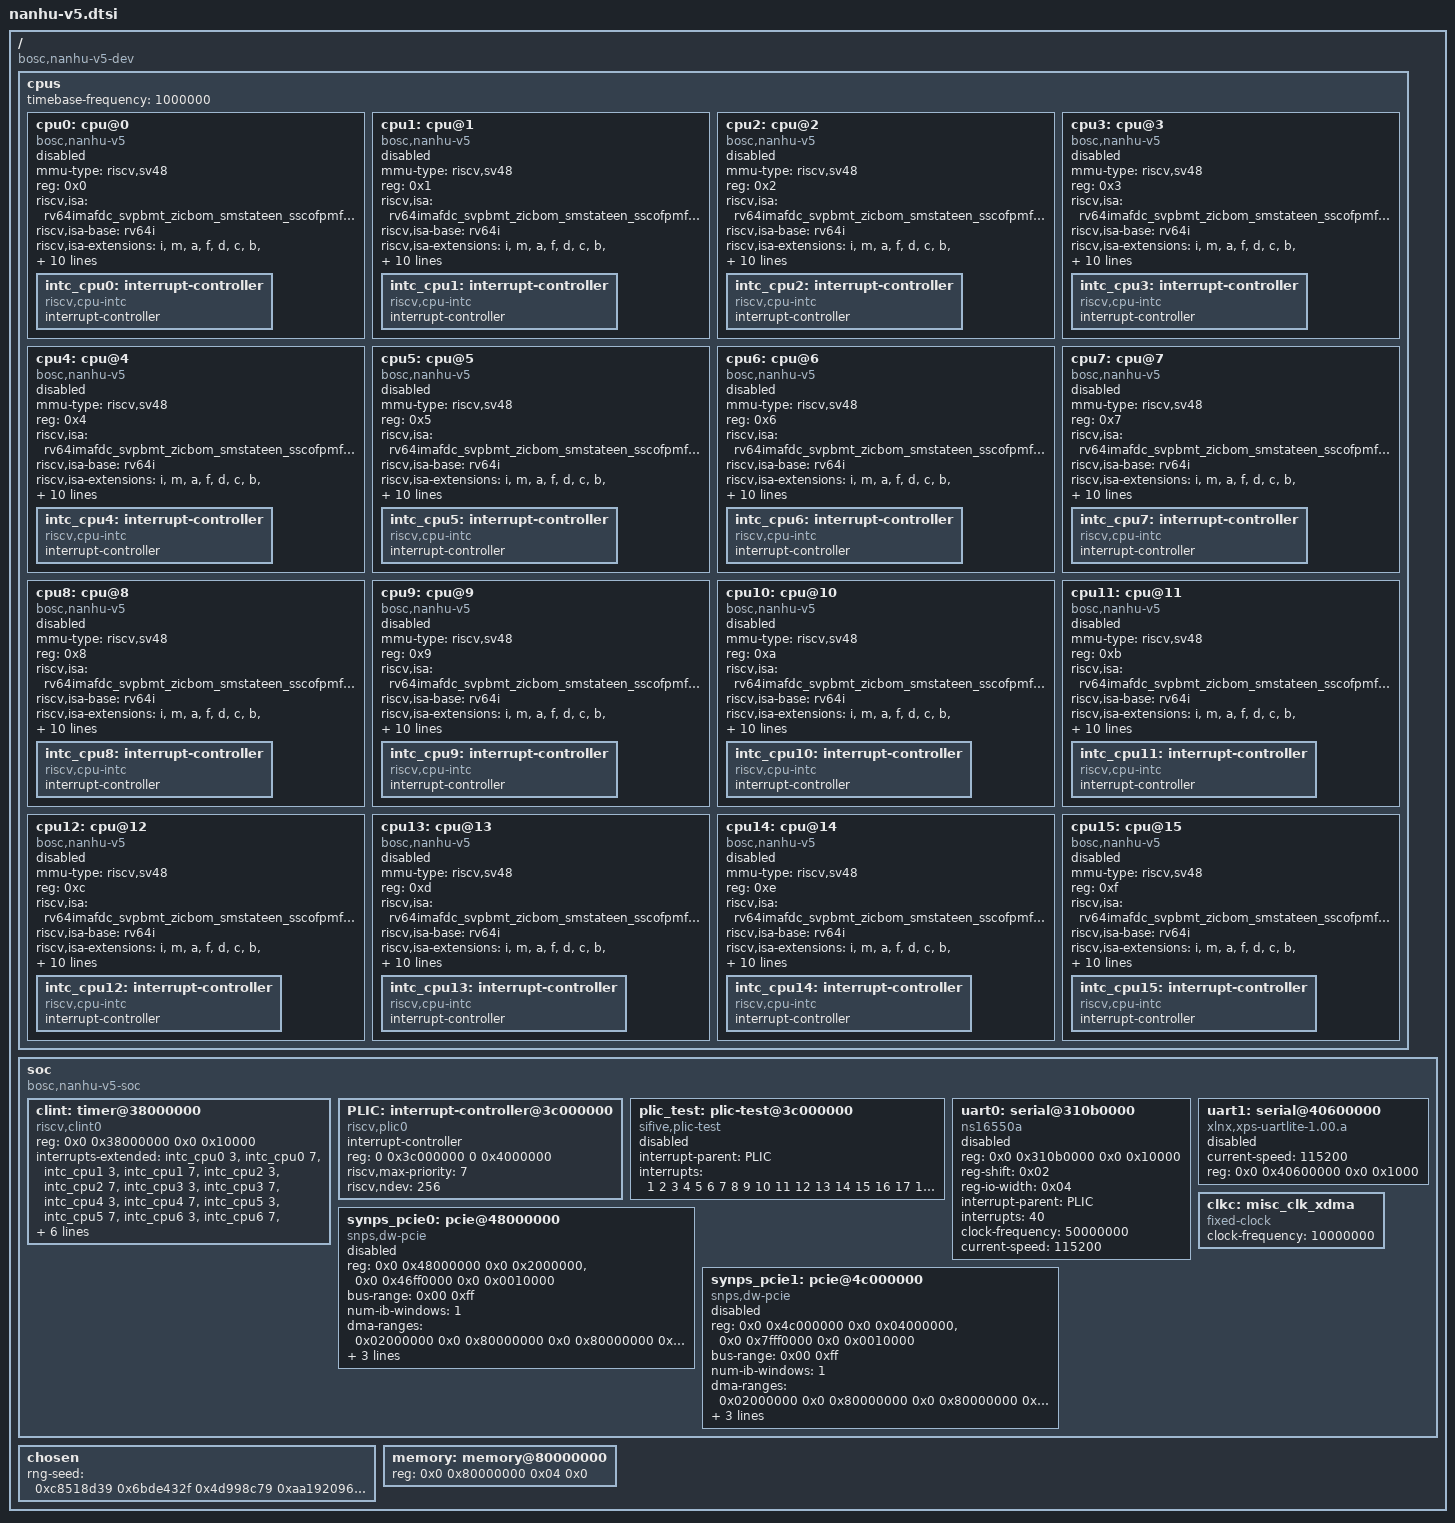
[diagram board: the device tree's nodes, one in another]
// SPDX-License-Identifier: (GPL-2.0 OR MIT)
/* Copyright (c) 2025 BOSC */

/dts-v1/;
#include <dt-bindings/interrupt-controller/irq.h>
/ {
	compatible = "bosc,nanhu-v5-dev";
	#address-cells = <2>;
	#size-cells = <2>;

	cpus {
		#address-cells = <1>;
		#size-cells = <0>;
		timebase-frequency = <1000000>; /* 1Mhz */

		cpu0: cpu@0 {
			compatible = "bosc,nanhu-v5", "riscv";
			device_type = "cpu";
			mmu-type = "riscv,sv48";
			reg = <0x0>;
			riscv,isa = "rv64imafdc_svpbmt_zicbom_smstateen_sscofpmf_zicntr_zihpm_zicboz_sdtrig_svade_zicboz_zicbom";
			riscv,isa-base = "rv64i";
			riscv,isa-extensions = "i", "m", "a", "f", "d", "c","b", "zifencei","zicsr","zicntr", "zihpm", "zba", "zbb", "zbc", "zbs", "zkn", "zknd", "zkne","zknh", "zks", "zksed",
						"zksh", "zkt","zicbom","zicbop", "zicboz","zicond","zimop", "zcmop","zcb", "zbkb", "zbkc", "zbkx", "svpbmt", "svinval","sstc",
						"sscofpmf", "ssstateen", "smstateen", "ziccif", "ziccrse", "ziccamoa", "za64rs", "zic64b", "svbare", "svade", "ssccptr", "sscounterenw",
						"sstvecd", "sstvala", "ssu64xl";

			riscv,cbom-block-size = <0x40>;
			riscv,cboz-block-size = <0x40>;

                        status = "disabled";

			intc_cpu0: interrupt-controller {
				#interrupt-cells = <1>;
				compatible = "riscv,cpu-intc";
				interrupt-controller;
			};
		};

		cpu1: cpu@1 {
			compatible = "bosc,nanhu-v5", "riscv";
			device_type = "cpu";
			mmu-type = "riscv,sv48";
			reg = <0x1>;
			riscv,isa = "rv64imafdc_svpbmt_zicbom_smstateen_sscofpmf_zicntr_zihpm_zicboz_sdtrig_svade_zicboz_zicbom";
			riscv,isa-base = "rv64i";
			riscv,isa-extensions = "i", "m", "a", "f", "d", "c","b", "zifencei","zicsr","zicntr", "zihpm", "zba", "zbb", "zbc", "zbs", "zkn", "zknd", "zkne","zknh", "zks", "zksed",
						"zksh", "zkt","zicbom","zicbop", "zicboz","zicond","zimop", "zcmop","zcb", "zbkb", "zbkc", "zbkx", "svpbmt", "svinval","sstc",
						"sscofpmf", "ssstateen", "smstateen", "ziccif", "ziccrse", "ziccamoa", "za64rs", "zic64b", "svbare", "svade", "ssccptr", "sscounterenw",
						"sstvecd", "sstvala", "ssu64xl";
			riscv,cbom-block-size = <0x40>;
			riscv,cboz-block-size = <0x40>;

                        status = "disabled";

			intc_cpu1: interrupt-controller {
				#interrupt-cells = <1>;
				compatible = "riscv,cpu-intc";
				interrupt-controller;
			};
		};

		cpu2: cpu@2 {
			compatible = "bosc,nanhu-v5", "riscv";
			device_type = "cpu";
			mmu-type = "riscv,sv48";
			reg = <0x2>;
			riscv,isa = "rv64imafdc_svpbmt_zicbom_smstateen_sscofpmf_zicntr_zihpm_zicboz_sdtrig_svade_zicboz_zicbom";
			riscv,isa-base = "rv64i";
			riscv,isa-extensions = "i", "m", "a", "f", "d", "c","b", "zifencei","zicsr","zicntr", "zihpm", "zba", "zbb", "zbc", "zbs", "zkn", "zknd", "zkne","zknh", "zks", "zksed",
						"zksh", "zkt","zicbom","zicbop", "zicboz","zicond","zimop", "zcmop","zcb", "zbkb", "zbkc", "zbkx", "svpbmt", "svinval","sstc",
						"sscofpmf", "ssstateen", "smstateen", "ziccif", "ziccrse", "ziccamoa", "za64rs", "zic64b", "svbare", "svade", "ssccptr", "sscounterenw",
						"sstvecd", "sstvala", "ssu64xl";
			riscv,cbom-block-size = <0x40>;
			riscv,cboz-block-size = <0x40>;

                        status = "disabled";

			intc_cpu2: interrupt-controller {
				#interrupt-cells = <1>;
				compatible = "riscv,cpu-intc";
				interrupt-controller;
			};
		};

		cpu3: cpu@3 {
			compatible = "bosc,nanhu-v5", "riscv";
			device_type = "cpu";
			mmu-type = "riscv,sv48";
			reg = <0x3>;
			riscv,isa = "rv64imafdc_svpbmt_zicbom_smstateen_sscofpmf_zicntr_zihpm_zicboz_sdtrig_svade_zicboz_zicbom";
			riscv,isa-base = "rv64i";
			riscv,isa-extensions = "i", "m", "a", "f", "d", "c","b", "zifencei","zicsr","zicntr", "zihpm", "zba", "zbb", "zbc", "zbs", "zkn", "zknd", "zkne","zknh", "zks", "zksed",
						"zksh", "zkt","zicbom","zicbop", "zicboz","zicond","zimop", "zcmop","zcb", "zbkb", "zbkc", "zbkx", "svpbmt", "svinval","sstc",
						"sscofpmf", "ssstateen", "smstateen", "ziccif", "ziccrse", "ziccamoa", "za64rs", "zic64b", "svbare", "svade", "ssccptr", "sscounterenw",
						"sstvecd", "sstvala", "ssu64xl";
			riscv,cbom-block-size = <0x40>;
			riscv,cboz-block-size = <0x40>;

                        status = "disabled";

			intc_cpu3: interrupt-controller {
				#interrupt-cells = <1>;
				compatible = "riscv,cpu-intc";
				interrupt-controller;
			};
		};

		cpu4: cpu@4 {
			compatible = "bosc,nanhu-v5", "riscv";
			device_type = "cpu";
			mmu-type = "riscv,sv48";
			reg = <0x4>;
			riscv,isa = "rv64imafdc_svpbmt_zicbom_smstateen_sscofpmf_zicntr_zihpm_zicboz_sdtrig_svade_zicboz_zicbom";
			riscv,isa-base = "rv64i";
			riscv,isa-extensions = "i", "m", "a", "f", "d", "c","b", "zifencei","zicsr","zicntr", "zihpm", "zba", "zbb", "zbc", "zbs", "zkn", "zknd", "zkne","zknh", "zks", "zksed",
						"zksh", "zkt","zicbom","zicbop", "zicboz","zicond","zimop", "zcmop","zcb", "zbkb", "zbkc", "zbkx", "svpbmt", "svinval","sstc",
						"sscofpmf", "ssstateen", "smstateen", "ziccif", "ziccrse", "ziccamoa", "za64rs", "zic64b", "svbare", "svade", "ssccptr", "sscounterenw",
						"sstvecd", "sstvala", "ssu64xl";
			riscv,cbom-block-size = <0x40>;
			riscv,cboz-block-size = <0x40>;

                        status = "disabled";

			intc_cpu4: interrupt-controller {
				#interrupt-cells = <1>;
				compatible = "riscv,cpu-intc";
				interrupt-controller;
			};
		};

		cpu5: cpu@5 {
			compatible = "bosc,nanhu-v5", "riscv";
			device_type = "cpu";
			mmu-type = "riscv,sv48";
			reg = <0x5>;
			riscv,isa = "rv64imafdc_svpbmt_zicbom_smstateen_sscofpmf_zicntr_zihpm_zicboz_sdtrig_svade_zicboz_zicbom";
			riscv,isa-base = "rv64i";
			riscv,isa-extensions = "i", "m", "a", "f", "d", "c","b", "zifencei","zicsr","zicntr", "zihpm", "zba", "zbb", "zbc", "zbs", "zkn", "zknd", "zkne","zknh", "zks", "zksed",
						"zksh", "zkt","zicbom","zicbop", "zicboz","zicond","zimop", "zcmop","zcb", "zbkb", "zbkc", "zbkx", "svpbmt", "svinval","sstc",
						"sscofpmf", "ssstateen", "smstateen", "ziccif", "ziccrse", "ziccamoa", "za64rs", "zic64b", "svbare", "svade", "ssccptr", "sscounterenw",
						"sstvecd", "sstvala", "ssu64xl";
			riscv,cbom-block-size = <0x40>;
			riscv,cboz-block-size = <0x40>;

                        status = "disabled";

			intc_cpu5: interrupt-controller {
				#interrupt-cells = <1>;
				compatible = "riscv,cpu-intc";
				interrupt-controller;
			};
		};

		cpu6: cpu@6 {
			compatible = "bosc,nanhu-v5", "riscv";
			device_type = "cpu";
			mmu-type = "riscv,sv48";
			reg = <0x6>;
			riscv,isa = "rv64imafdc_svpbmt_zicbom_smstateen_sscofpmf_zicntr_zihpm_zicboz_sdtrig_svade_zicboz_zicbom";
			riscv,isa-base = "rv64i";
			riscv,isa-extensions = "i", "m", "a", "f", "d", "c","b", "zifencei","zicsr","zicntr", "zihpm", "zba", "zbb", "zbc", "zbs", "zkn", "zknd", "zkne","zknh", "zks", "zksed",
						"zksh", "zkt","zicbom","zicbop", "zicboz","zicond","zimop", "zcmop","zcb", "zbkb", "zbkc", "zbkx", "svpbmt", "svinval","sstc",
						"sscofpmf", "ssstateen", "smstateen", "ziccif", "ziccrse", "ziccamoa", "za64rs", "zic64b", "svbare", "svade", "ssccptr", "sscounterenw",
						"sstvecd", "sstvala", "ssu64xl";
			riscv,cbom-block-size = <0x40>;
			riscv,cboz-block-size = <0x40>;

                        status = "disabled";

			intc_cpu6: interrupt-controller {
				#interrupt-cells = <1>;
				compatible = "riscv,cpu-intc";
				interrupt-controller;
			};
		};

		cpu7: cpu@7 {
			compatible = "bosc,nanhu-v5", "riscv";
			device_type = "cpu";
			mmu-type = "riscv,sv48";
			reg = <0x7>;
			riscv,isa = "rv64imafdc_svpbmt_zicbom_smstateen_sscofpmf_zicntr_zihpm_zicboz_sdtrig_svade_zicboz_zicbom";
			riscv,isa-base = "rv64i";
			riscv,isa-extensions = "i", "m", "a", "f", "d", "c","b", "zifencei","zicsr","zicntr", "zihpm", "zba", "zbb", "zbc", "zbs", "zkn", "zknd", "zkne","zknh", "zks", "zksed",
						"zksh", "zkt","zicbom","zicbop", "zicboz","zicond","zimop", "zcmop","zcb", "zbkb", "zbkc", "zbkx", "svpbmt", "svinval","sstc",
						"sscofpmf", "ssstateen", "smstateen", "ziccif", "ziccrse", "ziccamoa", "za64rs", "zic64b", "svbare", "svade", "ssccptr", "sscounterenw",
						"sstvecd", "sstvala", "ssu64xl";
			riscv,cbom-block-size = <0x40>;
			riscv,cboz-block-size = <0x40>;

                        status = "disabled";

			intc_cpu7: interrupt-controller {
				#interrupt-cells = <1>;
				compatible = "riscv,cpu-intc";
				interrupt-controller;
			};
		};

		cpu8: cpu@8 {
			compatible = "bosc,nanhu-v5", "riscv";
			device_type = "cpu";
			mmu-type = "riscv,sv48";
			reg = <0x8>;
			riscv,isa = "rv64imafdc_svpbmt_zicbom_smstateen_sscofpmf_zicntr_zihpm_zicboz_sdtrig_svade_zicboz_zicbom";
			riscv,isa-base = "rv64i";
			riscv,isa-extensions = "i", "m", "a", "f", "d", "c","b", "zifencei","zicsr","zicntr", "zihpm", "zba", "zbb", "zbc", "zbs", "zkn", "zknd", "zkne","zknh", "zks", "zksed",
						"zksh", "zkt","zicbom","zicbop", "zicboz","zicond","zimop", "zcmop","zcb", "zbkb", "zbkc", "zbkx", "svpbmt", "svinval","sstc",
						"sscofpmf", "ssstateen", "smstateen", "ziccif", "ziccrse", "ziccamoa", "za64rs", "zic64b", "svbare", "svade", "ssccptr", "sscounterenw",
						"sstvecd", "sstvala", "ssu64xl";
			riscv,cbom-block-size = <0x40>;
			riscv,cboz-block-size = <0x40>;

                        status = "disabled";

			intc_cpu8: interrupt-controller {
				#interrupt-cells = <1>;
				compatible = "riscv,cpu-intc";
				interrupt-controller;
			};
		};

		cpu9: cpu@9 {
			compatible = "bosc,nanhu-v5", "riscv";
			device_type = "cpu";
			mmu-type = "riscv,sv48";
			reg = <0x9>;
			riscv,isa = "rv64imafdc_svpbmt_zicbom_smstateen_sscofpmf_zicntr_zihpm_zicboz_sdtrig_svade_zicboz_zicbom";
			riscv,isa-base = "rv64i";
			riscv,isa-extensions = "i", "m", "a", "f", "d", "c","b", "zifencei","zicsr","zicntr", "zihpm", "zba", "zbb", "zbc", "zbs", "zkn", "zknd", "zkne","zknh", "zks", "zksed",
						"zksh", "zkt","zicbom","zicbop", "zicboz","zicond","zimop", "zcmop","zcb", "zbkb", "zbkc", "zbkx", "svpbmt", "svinval","sstc",
						"sscofpmf", "ssstateen", "smstateen", "ziccif", "ziccrse", "ziccamoa", "za64rs", "zic64b", "svbare", "svade", "ssccptr", "sscounterenw",
						"sstvecd", "sstvala", "ssu64xl";
			riscv,cbom-block-size = <0x40>;
			riscv,cboz-block-size = <0x40>;

                        status = "disabled";

			intc_cpu9: interrupt-controller {
				#interrupt-cells = <1>;
				compatible = "riscv,cpu-intc";
				interrupt-controller;
			};
		};

		cpu10: cpu@10 {
			compatible = "bosc,nanhu-v5", "riscv";
			device_type = "cpu";
			mmu-type = "riscv,sv48";
			reg = <0xa>;
			riscv,isa = "rv64imafdc_svpbmt_zicbom_smstateen_sscofpmf_zicntr_zihpm_zicboz_sdtrig_svade_zicboz_zicbom";
			riscv,isa-base = "rv64i";
			riscv,isa-extensions = "i", "m", "a", "f", "d", "c","b", "zifencei","zicsr","zicntr", "zihpm", "zba", "zbb", "zbc", "zbs", "zkn", "zknd", "zkne","zknh", "zks", "zksed",
						"zksh", "zkt","zicbom","zicbop", "zicboz","zicond","zimop", "zcmop","zcb", "zbkb", "zbkc", "zbkx", "svpbmt", "svinval","sstc",
						"sscofpmf", "ssstateen", "smstateen", "ziccif", "ziccrse", "ziccamoa", "za64rs", "zic64b", "svbare", "svade", "ssccptr", "sscounterenw",
						"sstvecd", "sstvala", "ssu64xl";
			riscv,cbom-block-size = <0x40>;
			riscv,cboz-block-size = <0x40>;

                        status = "disabled";

			intc_cpu10: interrupt-controller {
				#interrupt-cells = <1>;
				compatible = "riscv,cpu-intc";
				interrupt-controller;
			};
		};

		cpu11: cpu@11 {
			compatible = "bosc,nanhu-v5", "riscv";
			device_type = "cpu";
			mmu-type = "riscv,sv48";
			reg = <0xb>;
			riscv,isa = "rv64imafdc_svpbmt_zicbom_smstateen_sscofpmf_zicntr_zihpm_zicboz_sdtrig_svade_zicboz_zicbom";
			riscv,isa-base = "rv64i";
			riscv,isa-extensions = "i", "m", "a", "f", "d", "c","b", "zifencei","zicsr","zicntr", "zihpm", "zba", "zbb", "zbc", "zbs", "zkn", "zknd", "zkne","zknh", "zks", "zksed",
						"zksh", "zkt","zicbom","zicbop", "zicboz","zicond","zimop", "zcmop","zcb", "zbkb", "zbkc", "zbkx", "svpbmt", "svinval","sstc",
						"sscofpmf", "ssstateen", "smstateen", "ziccif", "ziccrse", "ziccamoa", "za64rs", "zic64b", "svbare", "svade", "ssccptr", "sscounterenw",
						"sstvecd", "sstvala", "ssu64xl";
			riscv,cbom-block-size = <0x40>;
			riscv,cboz-block-size = <0x40>;

                        status = "disabled";

			intc_cpu11: interrupt-controller {
				#interrupt-cells = <1>;
				compatible = "riscv,cpu-intc";
				interrupt-controller;
			};
		};

		cpu12: cpu@12 {
			compatible = "bosc,nanhu-v5", "riscv";
			device_type = "cpu";
			mmu-type = "riscv,sv48";
			reg = <0xc>;
			riscv,isa = "rv64imafdc_svpbmt_zicbom_smstateen_sscofpmf_zicntr_zihpm_zicboz_sdtrig_svade_zicboz_zicbom";
			riscv,isa-base = "rv64i";
			riscv,isa-extensions = "i", "m", "a", "f", "d", "c","b", "zifencei","zicsr","zicntr", "zihpm", "zba", "zbb", "zbc", "zbs", "zkn", "zknd", "zkne","zknh", "zks", "zksed",
						"zksh", "zkt","zicbom","zicbop", "zicboz","zicond","zimop", "zcmop","zcb", "zbkb", "zbkc", "zbkx", "svpbmt", "svinval","sstc",
						"sscofpmf", "ssstateen", "smstateen", "ziccif", "ziccrse", "ziccamoa", "za64rs", "zic64b", "svbare", "svade", "ssccptr", "sscounterenw",
						"sstvecd", "sstvala", "ssu64xl";
			riscv,cbom-block-size = <0x40>;
			riscv,cboz-block-size = <0x40>;

                        status = "disabled";

			intc_cpu12: interrupt-controller {
				#interrupt-cells = <1>;
				compatible = "riscv,cpu-intc";
				interrupt-controller;
			};
		};

		cpu13: cpu@13 {
			compatible = "bosc,nanhu-v5", "riscv";
			device_type = "cpu";
			mmu-type = "riscv,sv48";
			reg = <0xd>;
			riscv,isa = "rv64imafdc_svpbmt_zicbom_smstateen_sscofpmf_zicntr_zihpm_zicboz_sdtrig_svade_zicboz_zicbom";
			riscv,isa-base = "rv64i";
			riscv,isa-extensions = "i", "m", "a", "f", "d", "c","b", "zifencei","zicsr","zicntr", "zihpm", "zba", "zbb", "zbc", "zbs", "zkn", "zknd", "zkne","zknh", "zks", "zksed",
						"zksh", "zkt","zicbom","zicbop", "zicboz","zicond","zimop", "zcmop","zcb", "zbkb", "zbkc", "zbkx", "svpbmt", "svinval","sstc",
						"sscofpmf", "ssstateen", "smstateen", "ziccif", "ziccrse", "ziccamoa", "za64rs", "zic64b", "svbare", "svade", "ssccptr", "sscounterenw",
						"sstvecd", "sstvala", "ssu64xl";
			riscv,cbom-block-size = <0x40>;
			riscv,cboz-block-size = <0x40>;

                        status = "disabled";

			intc_cpu13: interrupt-controller {
				#interrupt-cells = <1>;
				compatible = "riscv,cpu-intc";
				interrupt-controller;
			};
		};

		cpu14: cpu@14 {
			compatible = "bosc,nanhu-v5", "riscv";
			device_type = "cpu";
			mmu-type = "riscv,sv48";
			reg = <0xe>;
			riscv,isa = "rv64imafdc_svpbmt_zicbom_smstateen_sscofpmf_zicntr_zihpm_zicboz_sdtrig_svade_zicboz_zicbom";
			riscv,isa-base = "rv64i";
			riscv,isa-extensions = "i", "m", "a", "f", "d", "c","b", "zifencei","zicsr","zicntr", "zihpm", "zba", "zbb", "zbc", "zbs", "zkn", "zknd", "zkne","zknh", "zks", "zksed",
						"zksh", "zkt","zicbom","zicbop", "zicboz","zicond","zimop", "zcmop","zcb", "zbkb", "zbkc", "zbkx", "svpbmt", "svinval","sstc",
						"sscofpmf", "ssstateen", "smstateen", "ziccif", "ziccrse", "ziccamoa", "za64rs", "zic64b", "svbare", "svade", "ssccptr", "sscounterenw",
						"sstvecd", "sstvala", "ssu64xl";
			riscv,cbom-block-size = <0x40>;
			riscv,cboz-block-size = <0x40>;

                        status = "disabled";

			intc_cpu14: interrupt-controller {
				#interrupt-cells = <1>;
				compatible = "riscv,cpu-intc";
				interrupt-controller;
			};
		};

		cpu15: cpu@15 {
			compatible = "bosc,nanhu-v5", "riscv";
			device_type = "cpu";
			mmu-type = "riscv,sv48";
			reg = <0xf>;
			riscv,isa = "rv64imafdc_svpbmt_zicbom_smstateen_sscofpmf_zicntr_zihpm_zicboz_sdtrig_svade_zicboz_zicbom";
			riscv,isa-base = "rv64i";
			riscv,isa-extensions = "i", "m", "a", "f", "d", "c","b", "zifencei","zicsr","zicntr", "zihpm", "zba", "zbb", "zbc", "zbs", "zkn", "zknd", "zkne","zknh", "zks", "zksed",
						"zksh", "zkt","zicbom","zicbop", "zicboz","zicond","zimop", "zcmop","zcb", "zbkb", "zbkc", "zbkx", "svpbmt", "svinval","sstc",
						"sscofpmf", "ssstateen", "smstateen", "ziccif", "ziccrse", "ziccamoa", "za64rs", "zic64b", "svbare", "svade", "ssccptr", "sscounterenw",
						"sstvecd", "sstvala", "ssu64xl";
			riscv,cbom-block-size = <0x40>;
			riscv,cboz-block-size = <0x40>;

                        status = "disabled";

			intc_cpu15: interrupt-controller {
				#interrupt-cells = <1>;
				compatible = "riscv,cpu-intc";
				interrupt-controller;
			};
		};
	};

	soc {
		#address-cells = <2>;
		#size-cells = <2>;
		compatible = "bosc,nanhu-v5-soc", "simple-bus";
		ranges;

		clint: timer@38000000 {
			compatible = "riscv,clint0";
			reg = <0x0 0x38000000 0x0 0x10000>;
			interrupts-extended =
				<&intc_cpu0 3>, <&intc_cpu0 7>,
				<&intc_cpu1 3>, <&intc_cpu1 7>,
				<&intc_cpu2 3>, <&intc_cpu2 7>,
				<&intc_cpu3 3>, <&intc_cpu3 7>,
				<&intc_cpu4 3>, <&intc_cpu4 7>,
				<&intc_cpu5 3>, <&intc_cpu5 7>,
				<&intc_cpu6 3>, <&intc_cpu6 7>,
				<&intc_cpu7 3>, <&intc_cpu7 7>,
				<&intc_cpu8 3>, <&intc_cpu8 7>,
				<&intc_cpu9 3>, <&intc_cpu9 7>,
				<&intc_cpu10 3>, <&intc_cpu10 7>,
				<&intc_cpu11 3>, <&intc_cpu11 7>,
				<&intc_cpu12 3>, <&intc_cpu12 7>,
				<&intc_cpu13 3>, <&intc_cpu13 7>,
				<&intc_cpu14 3>, <&intc_cpu14 7>,
				<&intc_cpu15 3>, <&intc_cpu15 7>;
		};

		PLIC: interrupt-controller@3c000000 {
			#interrupt-cells = <1>;
			compatible = "riscv,plic0";
			interrupt-controller;
			reg = <0 0x3c000000 0 0x4000000>;
			reg-names = "control";
			riscv,max-priority = <7>;
			riscv,ndev = <256>;
		};

		plic_test: plic-test@3c000000 {
			compatible = "sifive,plic-test";
			interrupt-parent = <&PLIC>;
			/* 定义需要测试的中断号 */
			interrupt-names = "1", "2", "3", "4", "5", "6", "7", "8", "9", "10", "11", "12", "13", "14", "15", "16", "17", "18", "19", "20",
							  "21", "22", "23", "24", "25", "26", "27", "28", "29", "30", "31", "32", "33", "34", "35", "36", "37", "38", "39",
							  "41", "42", "43", "44", "45", "46", "47", "48", "49", "50", "51", "52", "53", "54", "55", "56", "57", "58",
							  "59", "60", "61", "62", "63", "64", "65", "66", "67", "68", "69", "70", "71", "72", "73", "74", "75", "76",
							  "77", "78", "79", "80", "81", "82", "83", "84", "85", "86", "87", "88", "89", "90", "91", "92", "93", "94",
							  "95", "96", "97", "98", "99", "100", "101", "102", "103", "104", "105", "106", "107", "108", "109", "110",
							  "111", "112", "113", "114", "115", "116", "117", "118", "119", "120", "121", "122", "123", "124", "125", "126",
							  "127", "128", "129", "130", "131", "132", "133", "134", "135", "136", "137", "138", "139", "140", "141", "142",
							  "143", "144", "145", "146", "147", "148", "149", "150", "151", "152", "153", "154", "155", "156", "157", "158",
							  "159", "160", "161", "162", "163", "164", "165", "166", "167", "168", "169", "170", "171", "172", "173", "174",
							  "175", "176", "177", "178", "179", "180", "181", "182", "183", "184", "185", "186", "187", "188", "189", "190",
							  "191", "192", "193", "194", "195", "196", "197", "198", "199", "200", "201", "202", "203", "204", "205", "206",
							  "207", "208", "209", "210", "211", "212", "213", "214", "215", "216", "217", "218", "219", "220", "221", "222",
							  "223", "224", "225", "226", "227", "228", "229", "230", "231", "232", "233", "234", "235", "236", "237", "238",
							  "239", "240", "241", "242", "243", "244", "245", "246", "247", "248", "249", "250", "251", "252", "253", "254", "255", "256";
			interrupts = <1    2    3    4    5    6    7    8    9    10    11    12    13    14  
						  15    16    17    18    19    20    21    22    23    24    25    26    27    28  
						  29    30    31    32    33    34    35    36    37    38    39    41    42  
						  43    44    45    46    47    48    49    50    51    52    53    54    55    56  
						  57    58    59    60    61    62    63    64    65    66    67    68    69    70  
						  71    72    73    74    75    76    77    78    79    80    81    82    83    84  
						  85    86    87    88    89    90    91    92    93    94    95    96    97    98  
						  99    100    101    102    103    104    105    106    107    108    109    110    111  
						  112    113    114    115    116    117    118    119    120    121    122    123    124  
						  125    126    127    128    129    130    131    132    133    134    135    136    137  
						  138    139    140    141    142    143    144    145    146    147    148    149    150  
						  151    152    153    154    155    156    157    158    159    160    161    162    163  
						  164    165    166    167    168    169    170    171    172    173    174    175    176  
						  177    178    179    180    181    182    183    184    185    186    187    188    189  
						  190    191    192    193    194    195    196    197    198    199    200    201    202  
						  203    204    205    206    207    208    209    210    211    212    213    214    215  
						  216    217    218    219    220    221    222    223    224    225    226    227    228  
						  229    230    231    232    233    234    235    236    237    238    239    240    241  
						  242    243    244    245    246    247    248    249    250    251    252    253    254  
						  255    256 >;
			status = "disabled";
		};

		uart0: serial@310b0000 {
			compatible = "ns16550a";
			reg = <0x0 0x310b0000 0x0 0x10000>;
			reg-shift = <0x02>;
			reg-io-width = <0x04>;
			interrupt-parent = <&PLIC>;
			interrupts = <40>;
			clock-frequency = <50000000>;
			current-speed = <115200>;
			status = "disabled";
		};

		uart1: serial@40600000 {
			compatible = "xlnx,xps-uartlite-1.00.a";
			current-speed = <115200>;
			reg = <0x0 0x40600000 0x0 0x1000>;
			reg-names = "control";
			status = "disabled";
		};

		clkc: misc_clk_xdma {
			#clock-cells = <0>;
			clock-frequency = <10000000>;
			compatible = "fixed-clock";
		};
		synps_pcie0: pcie@48000000 {
			compatible = "snps,dw-pcie";
			reg = <0x0 0x48000000 0x0 0x2000000>,
			      <0x0 0x46ff0000 0x0 0x0010000>;
			reg-names = "dbi", "config";
			#address-cells = <3>;
			#size-cells = <2>;
			device_type = "pci";
			bus-range = <0x00 0xff>;
			ranges = <0x02000000 0x00000000 0x40000000 0x00000000 0x40000000 0x00000000 0x6ff0000>; //128MB

			num-ib-windows = <1>;
			dma-ranges = <0x02000000 0x0 0x80000000 0x0 0x80000000 0x0 0x80000000>;

			interrupt-parent = <&PLIC>;
			interrupt-names = "msi", "hp";
			interrupts = <52 53>;
			num-lanes = <1>;
			status = "disable";
		};
		synps_pcie1: pcie@4c000000 {
			compatible = "snps,dw-pcie";
			reg = <0x0 0x4c000000 0x0 0x04000000>,
			      <0x0 0x7fff0000 0x0 0x0010000>;
			reg-names = "dbi", "config";
			#address-cells = <3>;
			#size-cells = <2>;
			device_type = "pci";
			bus-range = <0x00 0xff>;
			ranges = <0x02000000 0x00000000 0x40000000 0x00000000 0x60000000 0x00000000 0x1fff0000>; //512MB

			num-ib-windows = <1>;
			dma-ranges = <0x02000000 0x0 0x80000000 0x0 0x80000000 0x0 0x80000000>;

			interrupt-parent = <&PLIC>;
			interrupt-names = "msi", "hp";
			interrupts = <58 59>;
			num-lanes = <1>;
			status = "disable";
		};
	};

	chosen {
		rng-seed = <0xc8518d39 0x6bde432f 0x4d998c79 0xaa192096 0xdbcf36f3 0x532f3ab3 0x965240fe 0xac379c0e>;
	};

	memory: memory@80000000 {
		device_type = "memory";
		reg = <0x0 0x80000000 0x04 0x0>;
	};
};
